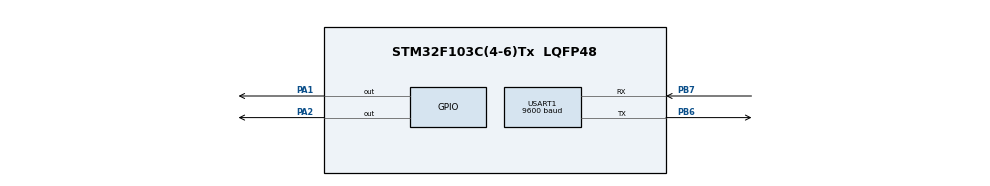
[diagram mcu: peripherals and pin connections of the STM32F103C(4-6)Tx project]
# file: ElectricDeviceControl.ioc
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Mcu.Family=STM32F1
Mcu.Name=STM32F103C(4-6)Tx
Mcu.Package=LQFP48
NVIC.PriorityGroup=NVIC_PRIORITYGROUP_4
NVIC.USART1_IRQn=true\:0\:0\:false\:true\:true\:1\:true\:true\:true
PA1.Signal=GPIO_Output
PA2.Signal=GPIO_Output
PB6.Mode=Asynchronous
PB6.Signal=USART1_TX
PB7.Mode=Asynchronous
PB7.Signal=USART1_RX
ProjectManager.HeapSize=0x200
ProjectManager.StackSize=0x400
ProjectManager.TargetToolchain=MDK-ARM V5
RCC.APB1Freq_Value=8000000
RCC.APB2Freq_Value=8000000
USART1.BaudRate=9600
USART1.VirtualMode=VM_ASYNC
VP_SYS_VS_ND.Mode=No_Debug
board=custom

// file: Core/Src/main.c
/* USER CODE BEGIN Header */
/**
 ******************************************************************************
 * @file           : main.c
 * @brief          : Main program body
 ******************************************************************************
 * @attention
 *
 * Copyright (c) 2024 STMicroelectronics.
 * All rights reserved.
 *
 * This software is licensed under terms that can be found in the LICENSE file
 * in the root directory of this software component.
 * If no LICENSE file comes with this software, it is provided AS-IS.
 *
 ******************************************************************************
 */
/* USER CODE END Header */
#include "main.h"

UART_HandleTypeDef huart1;

void SystemClock_Config(void);
static void MX_GPIO_Init(void);
static void MX_USART1_UART_Init(void);
static void MX_NVIC_Init(void);
uint8_t rx[10];
uint8_t tx_fan[] = "fanon";
uint8_t tx_light[] = "lighton";
uint8_t tx_fan_off[] = "fanoff";
uint8_t tx_light_off[] = "lightoff";

int main(void)
{

  /* MCU Configuration--------------------------------------------------------*/

  /* Reset of all peripherals, Initializes the Flash interface and the Systick. */
  HAL_Init();

  /* Configure the system clock */
  SystemClock_Config();

  /* Initialize all configured peripherals */
  MX_GPIO_Init();
  MX_USART1_UART_Init();

  /* Initialize interrupts */
  MX_NVIC_Init();
  /* USER CODE BEGIN 2 */
  HAL_UART_Init(&huart1);
  /* USER CODE END 2 */

  /* Infinite loop */
  while (1)
  {
    HAL_UART_Receive_IT(&huart1, rx, 1);
    if (rx[0] == 'a')
    {
      if (HAL_GPIO_ReadPin(GPIOA, GPIO_PIN_1) == 0)
      {
				HAL_UART_Transmit_IT(&huart1, tx_fan, strlen(tx_fan));
        HAL_GPIO_WritePin(GPIOA, GPIO_PIN_1, 1);
      }
      else
      {
        HAL_GPIO_WritePin(GPIOA, GPIO_PIN_1, 0);
				HAL_UART_Transmit_IT(&huart1, tx_fan_off, strlen(tx_fan_off));
      }
      rx[0] = 'd';
    }

    if (rx[0] == 'b')
    {
      if (HAL_GPIO_ReadPin(GPIOA, GPIO_PIN_2) == 0)
      {
				HAL_UART_Transmit_IT(&huart1, tx_light, strlen(tx_light));
        HAL_GPIO_WritePin(GPIOA, GPIO_PIN_2, 1);
      }
      else
      {
        HAL_GPIO_WritePin(GPIOA, GPIO_PIN_2, 0);
				HAL_UART_Transmit_IT(&huart1, tx_light_off, strlen(tx_light_off));
      }
      rx[0] = 'c';
    }

    if (rx[0] == 't')
    {
      HAL_GPIO_WritePin(GPIOA, GPIO_PIN_1, 0);
      HAL_GPIO_WritePin(GPIOA, GPIO_PIN_2, 0);
			rx[0] = 'k' ;
    }
  }
}

void SystemClock_Config(void)
{
  RCC_OscInitTypeDef RCC_OscInitStruct = {0};
  RCC_ClkInitTypeDef RCC_ClkInitStruct = {0};

  /** Initializes the RCC Oscillators according to the specified parameters
   * in the RCC_OscInitTypeDef structure.
   */
  RCC_OscInitStruct.OscillatorType = RCC_OSCILLATORTYPE_HSI;
  RCC_OscInitStruct.HSIState = RCC_HSI_ON;
  RCC_OscInitStruct.HSICalibrationValue = RCC_HSICALIBRATION_DEFAULT;
  RCC_OscInitStruct.PLL.PLLState = RCC_PLL_NONE;
  if (HAL_RCC_OscConfig(&RCC_OscInitStruct) != HAL_OK)
  {
    Error_Handler();
  }

  /** Initializes the CPU, AHB and APB buses clocks
   */
  RCC_ClkInitStruct.ClockType = RCC_CLOCKTYPE_HCLK | RCC_CLOCKTYPE_SYSCLK | RCC_CLOCKTYPE_PCLK1 | RCC_CLOCKTYPE_PCLK2;
  RCC_ClkInitStruct.SYSCLKSource = RCC_SYSCLKSOURCE_HSI;
  RCC_ClkInitStruct.AHBCLKDivider = RCC_SYSCLK_DIV1;
  RCC_ClkInitStruct.APB1CLKDivider = RCC_HCLK_DIV1;
  RCC_ClkInitStruct.APB2CLKDivider = RCC_HCLK_DIV1;

  if (HAL_RCC_ClockConfig(&RCC_ClkInitStruct, FLASH_LATENCY_0) != HAL_OK)
  {
    Error_Handler();
  }
}

/**
 * @brief NVIC Configuration.
 * @retval None
 */
static void MX_NVIC_Init(void)
{
  /* USART1_IRQn interrupt configuration */
  HAL_NVIC_SetPriority(USART1_IRQn, 0, 0);
  HAL_NVIC_EnableIRQ(USART1_IRQn);
}

static void MX_USART1_UART_Init(void)
{

  huart1.Instance = USART1;
  huart1.Init.BaudRate = 9600;
  huart1.Init.WordLength = UART_WORDLENGTH_8B;
  huart1.Init.StopBits = UART_STOPBITS_1;
  huart1.Init.Parity = UART_PARITY_NONE;
  huart1.Init.Mode = UART_MODE_TX_RX;
  huart1.Init.HwFlowCtl = UART_HWCONTROL_NONE;
  huart1.Init.OverSampling = UART_OVERSAMPLING_16;
  if (HAL_UART_Init(&huart1) != HAL_OK)
  {
    Error_Handler();
  }
}

static void MX_GPIO_Init(void)
{
  GPIO_InitTypeDef GPIO_InitStruct = {0};

  /* GPIO Ports Clock Enable */
  __HAL_RCC_GPIOA_CLK_ENABLE();
  __HAL_RCC_GPIOB_CLK_ENABLE();

  /*Configure GPIO pin Output Level */
  HAL_GPIO_WritePin(GPIOA, GPIO_PIN_1, GPIO_PIN_RESET);
  HAL_GPIO_WritePin(GPIOA, GPIO_PIN_2, GPIO_PIN_RESET);

  /*Configure GPIO pin : PA1 */
  GPIO_InitStruct.Pin = GPIO_PIN_1 | GPIO_PIN_2;
  GPIO_InitStruct.Mode = GPIO_MODE_OUTPUT_PP;
  GPIO_InitStruct.Pull = GPIO_NOPULL;
  GPIO_InitStruct.Speed = GPIO_SPEED_FREQ_LOW;
  HAL_GPIO_Init(GPIOA, &GPIO_InitStruct);

  //	 /*Configure GPIO pin : PA2 */
  //  GPIO_InitStruct.Pin = GPIO_PIN_2;
  //  GPIO_InitStruct.Mode = GPIO_MODE_OUTPUT_PP;
  //  GPIO_InitStruct.Pull = GPIO_NOPULL;
  //  GPIO_InitStruct.Speed = GPIO_SPEED_FREQ_LOW;
  //  HAL_GPIO_Init(GPIOA, &GPIO_InitStruct);

}

void Error_Handler(void)
{
  __disable_irq();
  while (1)
  {
  }
}
